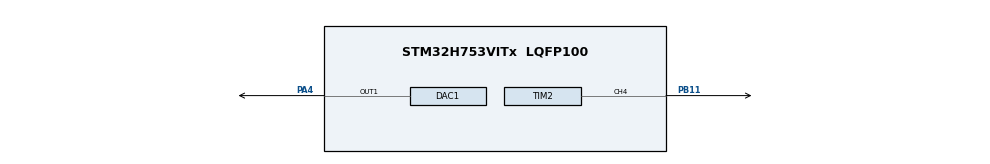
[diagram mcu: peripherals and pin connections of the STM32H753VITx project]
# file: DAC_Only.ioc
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DAC1.DAC_Channel-DAC_OUT1=DAC_CHANNEL_1
DAC1.DAC_Trigger-DAC_OUT1=DAC_TRIGGER_T2_TRGO
Dma.DAC1_CH1.0.Direction=DMA_MEMORY_TO_PERIPH
Dma.DAC1_CH1.0.EventEnable=DISABLE
Dma.DAC1_CH1.0.FIFOMode=DMA_FIFOMODE_DISABLE
Dma.DAC1_CH1.0.Instance=DMA1_Stream5
Dma.DAC1_CH1.0.MemDataAlignment=DMA_MDATAALIGN_WORD
Dma.DAC1_CH1.0.MemInc=DMA_MINC_ENABLE
Dma.DAC1_CH1.0.Mode=DMA_CIRCULAR
Dma.DAC1_CH1.0.PeriphDataAlignment=DMA_PDATAALIGN_WORD
Dma.DAC1_CH1.0.PeriphInc=DMA_PINC_DISABLE
Dma.DAC1_CH1.0.Polarity=HAL_DMAMUX_REQ_GEN_RISING
Dma.DAC1_CH1.0.Priority=DMA_PRIORITY_LOW
Dma.DAC1_CH1.0.RequestNumber=1
Dma.DAC1_CH1.0.SignalID=NONE
Dma.DAC1_CH1.0.SyncEnable=DISABLE
Dma.DAC1_CH1.0.SyncPolarity=HAL_DMAMUX_SYNC_NO_EVENT
Dma.DAC1_CH1.0.SyncRequestNumber=1
Dma.DAC1_CH1.0.SyncSignalID=NONE
Dma.Request0=DAC1_CH1
Mcu.Family=STM32H7
Mcu.Name=STM32H753VITx
Mcu.Package=LQFP100
NVIC.DMA1_Stream5_IRQn=true\:0\:0\:false\:false\:true\:false\:true\:true
NVIC.PriorityGroup=NVIC_PRIORITYGROUP_4
NVIC.TIM2_IRQn=true\:0\:0\:false\:false\:true\:true\:true\:true
NVIC.TIM6_DAC_IRQn=true\:0\:0\:false\:false\:true\:true\:true\:true
PA4.Signal=COMP_DAC11_group
PB11.Signal=S_TIM2_CH4
ProjectManager.HeapSize=0x200
ProjectManager.StackSize=0x400
ProjectManager.TargetToolchain=STM32CubeIDE
RCC.ADCFreq_Value=129000000
RCC.APB1Freq_Value=48000000
RCC.APB2Freq_Value=48000000
RCC.APB3Freq_Value=48000000
RCC.APB4Freq_Value=48000000
RCC.CortexFreq_Value=48000000
RCC.DIVM1=4
RCC.DIVN1=12
RCC.DIVP1=4
RCC.HCLKFreq_Value=48000000
RCC.PLL2FRACN=0
RCC.PLL3FRACN=0
RCC.PLLFRACN=0
RCC.SYSCLKFreq_VALUE=48000000
RCC.SYSCLKSource=RCC_SYSCLKSOURCE_PLLCLK
RCC.USBFreq_Value=96000000
SH.COMP_DAC11_group.0=DAC1_OUT1,DAC_OUT1
SH.S_TIM2_CH4.0=TIM2_CH4,PWM Generation4 CH4
TIM2.Channel-PWM\ Generation4\ CH4=TIM_CHANNEL_4
TIM2.Period=3125
TIM2.Prescaler=48-1
TIM2.Pulse-PWM\ Generation4\ CH4=0
TIM2.TIM_MasterOutputTrigger=TIM_TRGO_UPDATE
VP_TIM2_VS_ClockSourceINT.Mode=Internal
board=custom

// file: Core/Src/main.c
/* USER CODE BEGIN Header */
/**
  ******************************************************************************
  * @file           : main.c
  * @brief          : Main program body
  ******************************************************************************
  * @attention
  *
  * Copyright (c) 2024 STMicroelectronics.
  * All rights reserved.
  *
  * This software is licensed under terms that can be found in the LICENSE file
  * in the root directory of this software component.
  * If no LICENSE file comes with this software, it is provided AS-IS.
  *
  ******************************************************************************
  */
/* USER CODE END Header */
#include "main.h"

/* USER CODE BEGIN PTD */
#define SIZE 16
/* USER CODE END PTD */

DAC_HandleTypeDef hdac1;
DMA_HandleTypeDef hdma_dac1_ch1;

TIM_HandleTypeDef htim2;

void SystemClock_Config(void);
static void MX_GPIO_Init(void);
static void MX_DMA_Init(void);
static void MX_DAC1_Init(void);
static void MX_TIM2_Init(void);

/* USER CODE BEGIN 0 */
uint32_t DAC_OUT[SIZE] = { 0, 0, 620, 1241, 1861, 2482, 3103, 3723, 4095, 4095, 3723, 3103, 2482, 1861, 1241, 620 }; // For 3.3 volts

/* USER CODE END 0 */

int main(void)
{

  /* MCU Configuration--------------------------------------------------------*/

  /* Reset of all peripherals, Initializes the Flash interface and the Systick. */
  HAL_Init();

  /* Configure the system clock */
  SystemClock_Config();

  /* Initialize all configured peripherals */
  MX_GPIO_Init();
  MX_DMA_Init();
  MX_DAC1_Init();
  MX_TIM2_Init();
  /* USER CODE BEGIN 2 */
  TIM2->CCR4 = 312;
  HAL_TIM_PWM_Start(&htim2, TIM_CHANNEL_4);

  HAL_TIM_Base_Start(&htim2);

  HAL_DAC_Start_DMA(&hdac1, DAC_CHANNEL_1, DAC_OUT, SIZE, DAC_ALIGN_12B_R);
  /* USER CODE END 2 */

  /* Infinite loop */
  while (1)
  {

  }
}

void SystemClock_Config(void)
{
  RCC_OscInitTypeDef RCC_OscInitStruct = {0};
  RCC_ClkInitTypeDef RCC_ClkInitStruct = {0};

  /** Supply configuration update enable
  */
  HAL_PWREx_ConfigSupply(PWR_LDO_SUPPLY);

  /** Configure the main internal regulator output voltage
  */
  __HAL_PWR_VOLTAGESCALING_CONFIG(PWR_REGULATOR_VOLTAGE_SCALE3);

  while(!__HAL_PWR_GET_FLAG(PWR_FLAG_VOSRDY)) {}

  /** Initializes the RCC Oscillators according to the specified parameters
  * in the RCC_OscInitTypeDef structure.
  */
  RCC_OscInitStruct.OscillatorType = RCC_OSCILLATORTYPE_HSI;
  RCC_OscInitStruct.HSIState = RCC_HSI_DIV1;
  RCC_OscInitStruct.HSICalibrationValue = RCC_HSICALIBRATION_DEFAULT;
  RCC_OscInitStruct.PLL.PLLState = RCC_PLL_ON;
  RCC_OscInitStruct.PLL.PLLSource = RCC_PLLSOURCE_HSI;
  RCC_OscInitStruct.PLL.PLLM = 4;
  RCC_OscInitStruct.PLL.PLLN = 12;
  RCC_OscInitStruct.PLL.PLLP = 4;
  RCC_OscInitStruct.PLL.PLLQ = 2;
  RCC_OscInitStruct.PLL.PLLR = 2;
  RCC_OscInitStruct.PLL.PLLRGE = RCC_PLL1VCIRANGE_3;
  RCC_OscInitStruct.PLL.PLLVCOSEL = RCC_PLL1VCOWIDE;
  RCC_OscInitStruct.PLL.PLLFRACN = 0;
  if (HAL_RCC_OscConfig(&RCC_OscInitStruct) != HAL_OK)
  {
    Error_Handler();
  }

  /** Initializes the CPU, AHB and APB buses clocks
  */
  RCC_ClkInitStruct.ClockType = RCC_CLOCKTYPE_HCLK|RCC_CLOCKTYPE_SYSCLK
                              |RCC_CLOCKTYPE_PCLK1|RCC_CLOCKTYPE_PCLK2
                              |RCC_CLOCKTYPE_D3PCLK1|RCC_CLOCKTYPE_D1PCLK1;
  RCC_ClkInitStruct.SYSCLKSource = RCC_SYSCLKSOURCE_PLLCLK;
  RCC_ClkInitStruct.SYSCLKDivider = RCC_SYSCLK_DIV1;
  RCC_ClkInitStruct.AHBCLKDivider = RCC_HCLK_DIV1;
  RCC_ClkInitStruct.APB3CLKDivider = RCC_APB3_DIV1;
  RCC_ClkInitStruct.APB1CLKDivider = RCC_APB1_DIV1;
  RCC_ClkInitStruct.APB2CLKDivider = RCC_APB2_DIV1;
  RCC_ClkInitStruct.APB4CLKDivider = RCC_APB4_DIV1;

  if (HAL_RCC_ClockConfig(&RCC_ClkInitStruct, FLASH_LATENCY_1) != HAL_OK)
  {
    Error_Handler();
  }
}

static void MX_DAC1_Init(void)
{

  DAC_ChannelConfTypeDef sConfig = {0};

  /** DAC Initialization
  */
  hdac1.Instance = DAC1;
  if (HAL_DAC_Init(&hdac1) != HAL_OK)
  {
    Error_Handler();
  }

  /** DAC channel OUT1 config
  */
  sConfig.DAC_SampleAndHold = DAC_SAMPLEANDHOLD_DISABLE;
  sConfig.DAC_Trigger = DAC_TRIGGER_T2_TRGO;
  sConfig.DAC_OutputBuffer = DAC_OUTPUTBUFFER_ENABLE;
  sConfig.DAC_ConnectOnChipPeripheral = DAC_CHIPCONNECT_DISABLE;
  sConfig.DAC_UserTrimming = DAC_TRIMMING_FACTORY;
  if (HAL_DAC_ConfigChannel(&hdac1, &sConfig, DAC_CHANNEL_1) != HAL_OK)
  {
    Error_Handler();
  }

}

static void MX_TIM2_Init(void)
{

  TIM_ClockConfigTypeDef sClockSourceConfig = {0};
  TIM_MasterConfigTypeDef sMasterConfig = {0};
  TIM_OC_InitTypeDef sConfigOC = {0};

  htim2.Instance = TIM2;
  htim2.Init.Prescaler = 48-1;
  htim2.Init.CounterMode = TIM_COUNTERMODE_UP;
  htim2.Init.Period = 3125;
  htim2.Init.ClockDivision = TIM_CLOCKDIVISION_DIV1;
  htim2.Init.AutoReloadPreload = TIM_AUTORELOAD_PRELOAD_DISABLE;
  if (HAL_TIM_Base_Init(&htim2) != HAL_OK)
  {
    Error_Handler();
  }
  sClockSourceConfig.ClockSource = TIM_CLOCKSOURCE_INTERNAL;
  if (HAL_TIM_ConfigClockSource(&htim2, &sClockSourceConfig) != HAL_OK)
  {
    Error_Handler();
  }
  if (HAL_TIM_PWM_Init(&htim2) != HAL_OK)
  {
    Error_Handler();
  }
  sMasterConfig.MasterOutputTrigger = TIM_TRGO_UPDATE;
  sMasterConfig.MasterSlaveMode = TIM_MASTERSLAVEMODE_DISABLE;
  if (HAL_TIMEx_MasterConfigSynchronization(&htim2, &sMasterConfig) != HAL_OK)
  {
    Error_Handler();
  }
  sConfigOC.OCMode = TIM_OCMODE_PWM1;
  sConfigOC.Pulse = 0;
  sConfigOC.OCPolarity = TIM_OCPOLARITY_HIGH;
  sConfigOC.OCFastMode = TIM_OCFAST_DISABLE;
  if (HAL_TIM_PWM_ConfigChannel(&htim2, &sConfigOC, TIM_CHANNEL_4) != HAL_OK)
  {
    Error_Handler();
  }
  HAL_TIM_MspPostInit(&htim2);

}

static void MX_DMA_Init(void)
{

  /* DMA controller clock enable */
  __HAL_RCC_DMA1_CLK_ENABLE();

  /* DMA interrupt init */
  /* DMA1_Stream5_IRQn interrupt configuration */
  HAL_NVIC_SetPriority(DMA1_Stream5_IRQn, 0, 0);
  HAL_NVIC_EnableIRQ(DMA1_Stream5_IRQn);

}

static void MX_GPIO_Init(void)
{

  /* GPIO Ports Clock Enable */
  __HAL_RCC_GPIOA_CLK_ENABLE();
  __HAL_RCC_GPIOB_CLK_ENABLE();

}

void Error_Handler(void)
{
  __disable_irq();
  while (1)
  {
  }
}
